VERSION ""

NS_ :

BS_:

BU_: XXX EPS

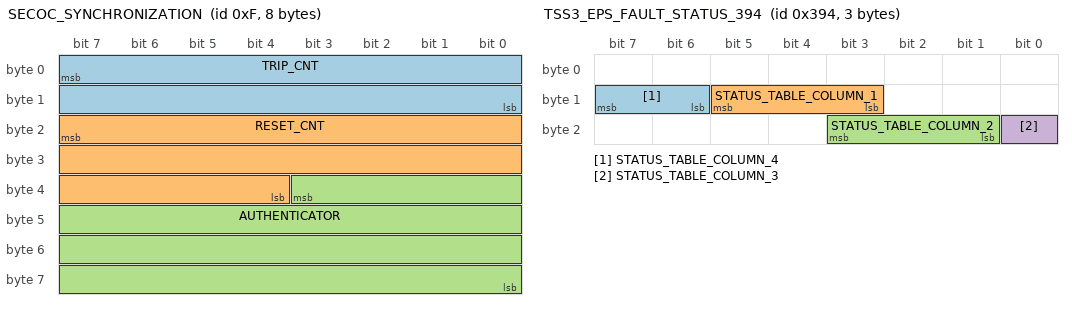
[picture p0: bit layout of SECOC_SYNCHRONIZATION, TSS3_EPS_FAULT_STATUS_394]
BO_ 15 SECOC_SYNCHRONIZATION: 8 XXX
 SG_ TRIP_CNT : 7|16@0+ (1,0) [0|65535] "" XXX
 SG_ RESET_CNT : 23|20@0+ (1,0) [0|1048575] "" XXX
 SG_ AUTHENTICATOR : 35|28@0+ (1,0) [0|268435455] "" XXX

BO_ 37 STEER_ANGLE_SENSOR: 32 XXX
 SG_ STEER_ANGLE : 3|12@0- (1.5,0) [-500|500] "deg" XXX
 SG_ STEER_FRACTION : 39|4@0- (0.1,0) [-0.7|0.7] "deg" XXX
 SG_ STEER_RATE : 35|12@0- (1,0) [-2000|2000] "deg/s" XXX

BO_ 48 TSS3_EPS_TELEMETRY: 32 EPS
 SG_ STEERING_WHEEL_TORQUE_TRUNC : 7|8@0- (0.1,0) [-12.8|12.7] "Nm" XXX
 SG_ EPS_STATUS_B6_BIT3 : 51|1@0+ (1,0) [0|1] "" XXX
 SG_ STEERING_FAULT_INHIBIT_STATUS : 50|1@0+ (1,0) [0|1] "" XXX
 SG_ EPS_STATUS_B6_BIT1 : 49|1@0+ (1,0) [0|1] "" XXX
 SG_ DRIVER_TORQUE_INVALID : 48|1@0+ (1,0) [0|1] "" XXX
 SG_ ADDITIVE_BYTE_7 : 63|8@0+ (1,0) [0|255] "" XXX
 SG_ STEERING_WHEEL_TORQUE_COARSE : 71|8@0- (0.1,0) [-12.8|12.7] "Nm" XXX
 SG_ STEERING_WHEEL_TORQUE_FINE : 139|4@0- (0.01,0) [-0.08|0.07] "Nm" XXX

BO_ 254 TSS3_CRUISE_SWITCH: 32 XXX
 SG_ MAIN_BUTTON : 58|1@0+ (1,0) [0|1] "" XXX
 SG_ RES_BUTTON : 31|1@0+ (1,0) [0|1] "" XXX
 SG_ RES_BUTTON_MIRROR_N : 55|1@0+ (1,0) [0|1] "" XXX
 SG_ SET_BUTTON : 39|1@0+ (1,0) [0|1] "" XXX
 SG_ SET_BUTTON_MIRROR_N : 62|1@0+ (1,0) [0|1] "" XXX
 SG_ CANCEL_BUTTON : 38|1@0+ (1,0) [0|1] "" XXX
 SG_ CANCEL_BUTTON_MIRROR_N : 61|1@0+ (1,0) [0|1] "" XXX

BO_ 138 TSS3_LATERAL_REQUEST: 32 XXX
 SG_ CRUISE_OPERATING_LATCH : 27|1@0+ (1,0) [0|1] "" XXX
 SG_ LATERAL_REQUEST_ACTIVE_FLAG : 39|1@0+ (1,0) [0|1] "" XXX
 SG_ CRUISE_SUBSTATE_1 : 55|8@0+ (1,0) [0|255] "" XXX
 SG_ CRUISE_SUBSTATE_2 : 63|8@0+ (1,0) [0|255] "" XXX
 SG_ REQUEST_WORD_B8 : 71|16@0- (1,0) [-32768|32767] "" XXX
 SG_ SET_SPEED : 87|8@0+ (1,0) [0|255] "km/h" XXX
 SG_ REQUEST_WORD_B8_MIRROR : 95|16@0- (1,0) [-32768|32767] "" XXX
 SG_ RESERVED_16BIT_B13 : 111|16@0- (1,0) [-32768|32767] "" XXX
 SG_ RESERVED_16BIT_B16 : 135|16@0- (1,0) [-32768|32767] "" XXX
 SG_ LATERAL_REQUEST_ANGLE : 151|16@0- (0.057302742,0) [-1877.696|1877.639] "deg" XXX
 SG_ CRUISE_STATE_B20 : 167|2@0+ (1,0) [0|3] "" XXX
 SG_ TARGET_LATERAL_ID : 173|6@0+ (1,0) [0|63] "" XXX
 SG_ CRUISE_STATE_B22 : 180|1@0+ (1,0) [0|1] "" XXX
 SG_ COOPERATIVE_SUBSTATE_FLAG : 189|1@0+ (1,0) [0|1] "" XXX
 SG_ LATERAL_REQUEST_LEVEL : 199|8@0+ (1,0) [0|255] "%" XXX
 SG_ SEQUENCE : 213|6@0+ (1,0) [0|63] "" XXX
 SG_ FRESHNESS_MESSAGE_LSB2 : 231|2@0+ (1,0) [0|3] "" XXX
 SG_ FRESHNESS_RESET_LSB2 : 229|2@0+ (1,0) [0|3] "" XXX
 SG_ CMAC_MSB28 : 227|28@0+ (1,0) [0|268435455] "" XXX

BO_ 849 TSS3_EPS_STATUS_351: 4 XXX
 SG_ STATUS_CODE : 23|3@0+ (1,0) [0|7] "" XXX
 SG_ STATUS_FLAG : 20|1@0+ (1,0) [0|1] "" XXX

BO_ 916 TSS3_EPS_FAULT_STATUS_394: 3 XXX
 SG_ STATUS_TABLE_COLUMN_4 : 15|2@0+ (1,0) [0|3] "" XXX
 SG_ STATUS_TABLE_COLUMN_1 : 13|3@0+ (1,0) [0|7] "" XXX
 SG_ STATUS_TABLE_COLUMN_2 : 19|3@0+ (1,0) [0|7] "" XXX
 SG_ STATUS_TABLE_COLUMN_3 : 16|1@0+ (1,0) [0|1] "" XXX

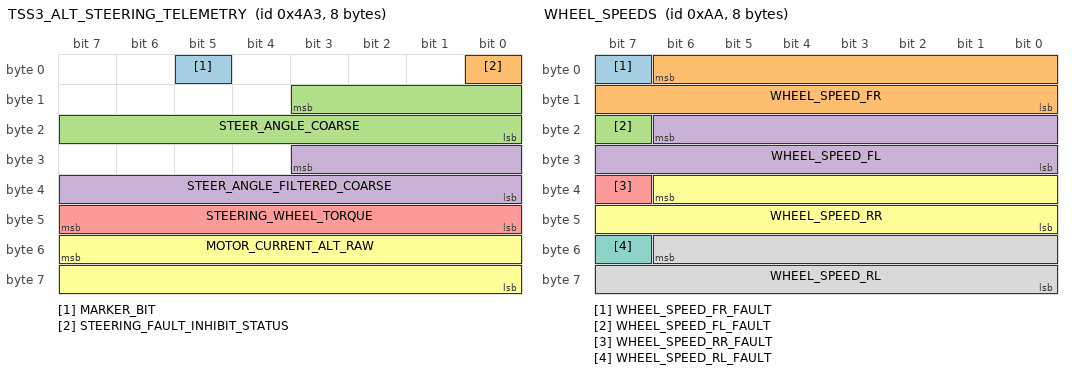
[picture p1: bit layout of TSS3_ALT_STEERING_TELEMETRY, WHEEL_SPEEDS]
BO_ 1187 TSS3_ALT_STEERING_TELEMETRY: 8 XXX
 SG_ MARKER_BIT : 5|1@0+ (1,0) [0|1] "" XXX
 SG_ STEERING_FAULT_INHIBIT_STATUS : 0|1@0+ (1,0) [0|1] "" XXX
 SG_ STEER_ANGLE_COARSE : 11|12@0- (1.5,0) [-3072|3070.5] "deg" XXX
 SG_ STEER_ANGLE_FILTERED_COARSE : 27|12@0- (1.5,0) [-3072|3070.5] "deg" XXX
 SG_ STEERING_WHEEL_TORQUE : 47|8@0- (0.1,0) [-12.8|12.7] "Nm" XXX
 SG_ MOTOR_CURRENT_ALT_RAW : 55|16@0- (1,0) [-32768|32767] "" XXX

BO_ 170 WHEEL_SPEEDS: 8 XXX
 SG_ WHEEL_SPEED_FR_FAULT : 7|1@0+ (1,0) [0|1] "" XXX
 SG_ WHEEL_SPEED_FR : 6|15@0+ (0.01,-67.67) [-67.67|260] "km/h" XXX
 SG_ WHEEL_SPEED_FL_FAULT : 23|1@0+ (1,0) [0|1] "" XXX
 SG_ WHEEL_SPEED_FL : 22|15@0+ (0.01,-67.67) [-67.67|260] "km/h" XXX
 SG_ WHEEL_SPEED_RR_FAULT : 39|1@0+ (1,0) [0|1] "" XXX
 SG_ WHEEL_SPEED_RR : 38|15@0+ (0.01,-67.67) [-67.67|260] "km/h" XXX
 SG_ WHEEL_SPEED_RL_FAULT : 55|1@0+ (1,0) [0|1] "" XXX
 SG_ WHEEL_SPEED_RL : 54|15@0+ (0.01,-67.67) [-67.67|260] "km/h" XXX

BO_ 182 TSS3_LATERAL_CONTROL: 32 XXX
 SG_ TARGET_LATERAL_ID : 29|6@0+ (1,0) [0|63] "" XXX
 SG_ TARGET_STEERING_ANGLE : 39|16@0- (0.057302742,0) [-99.9933|99.9933] "deg" XXX
 SG_ SIGNAL263_B6_BIT7 : 55|1@0+ (1,0) [0|1] "" XXX
 SG_ SIGNAL264_B6_BITS6_4 : 54|3@0+ (1,0) [0|7] "" XXX
 SG_ ADDITIVE_TERM_SUPPRESS : 50|1@0+ (1,0) [0|1] "" XXX
 SG_ SIGNAL266_B6_BITS1_0 : 49|2@0+ (1,0) [0|3] "" XXX
 SG_ SIGNAL267_B7_BITS7_6 : 63|2@0+ (1,0) [0|3] "" XXX
 SG_ SEQUENCE : 61|6@0+ (1,0) [0|63] "" XXX
 SG_ CONTRIBUTION_PCT_1 : 71|8@0+ (1,0) [0|255] "%" XXX
 SG_ CONTRIBUTION_PCT_2 : 79|8@0+ (1,0) [0|255] "%" XXX
 SG_ SIGNAL271_B10_BIT7 : 87|1@0+ (1,0) [0|1] "" XXX
 SG_ SIGNAL272_B10_BIT5 : 85|1@0+ (1,0) [0|1] "" XXX
 SG_ SIGNAL273_B10_BITS2_0 : 82|3@0+ (1,0) [0|7] "" XXX
 SG_ FRESHNESS_MESSAGE_LSB2 : 231|2@0+ (1,0) [0|3] "" XXX
 SG_ FRESHNESS_RESET_LSB2 : 229|2@0+ (1,0) [0|3] "" XXX
 SG_ CMAC_MSB28 : 227|28@0+ (1,0) [0|268435455] "" XXX

BO_ 593 TSS3_CRUISE_DISPLAY: 8 XXX
 SG_ CRUISE_MAIN_STATE : 12|1@0+ (1,0) [0|1] "" XXX
 SG_ UI_SET_SPEED : 23|8@0+ (1,0) [0|255] "" XXX

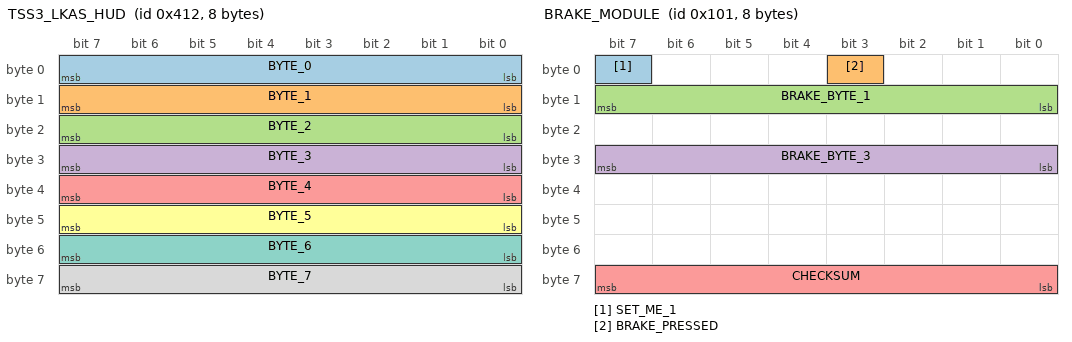
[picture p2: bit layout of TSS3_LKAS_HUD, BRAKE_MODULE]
BO_ 1042 TSS3_LKAS_HUD: 8 XXX
 SG_ BYTE_0 : 7|8@0+ (1,0) [0|255] "" XXX
 SG_ BYTE_1 : 15|8@0+ (1,0) [0|255] "" XXX
 SG_ BYTE_2 : 23|8@0+ (1,0) [0|255] "" XXX
 SG_ BYTE_3 : 31|8@0+ (1,0) [0|255] "" XXX
 SG_ BYTE_4 : 39|8@0+ (1,0) [0|255] "" XXX
 SG_ BYTE_5 : 47|8@0+ (1,0) [0|255] "" XXX
 SG_ BYTE_6 : 55|8@0+ (1,0) [0|255] "" XXX
 SG_ BYTE_7 : 63|8@0+ (1,0) [0|255] "" XXX

BO_ 257 BRAKE_MODULE: 8 XXX
 SG_ SET_ME_1 : 7|1@0+ (1,0) [0|1] "" XXX
 SG_ BRAKE_PRESSED : 3|1@0+ (1,0) [0|1] "" XXX
 SG_ BRAKE_BYTE_1 : 15|8@0+ (1,0) [0|255] "" XXX
 SG_ BRAKE_BYTE_3 : 31|8@0+ (1,0) [0|255] "" XXX
 SG_ CHECKSUM : 63|8@0+ (1,0) [0|255] "" XXX

BO_ 278 GAS_PEDAL: 8 XXX
 SG_ GAS_PEDAL_USER : 15|8@0+ (0.005,0) [0|1.275] "" XXX

BO_ 295 GEAR_PACKET_HYBRID: 8 XXX
 SG_ GEAR : 47|4@0+ (1,0) [0|15] "" XXX
 SG_ CHECKSUM : 63|8@0+ (1,0) [0|255] "" XXX

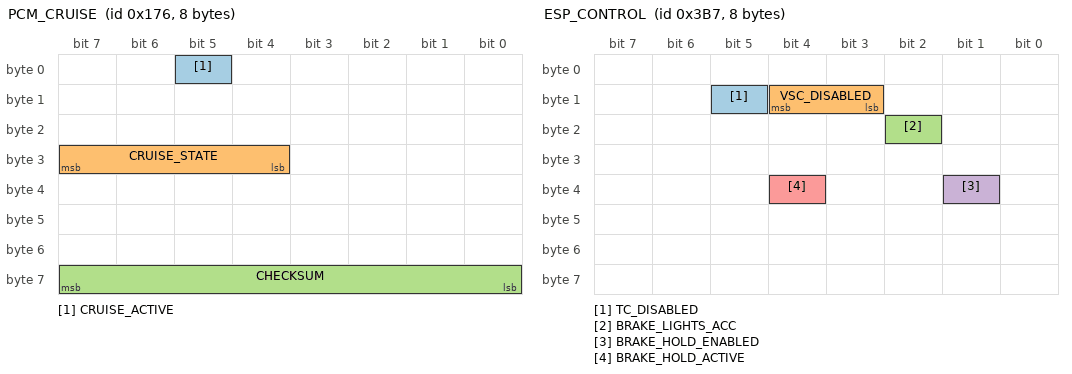
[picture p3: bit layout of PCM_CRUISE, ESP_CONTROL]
BO_ 374 PCM_CRUISE: 8 XXX
 SG_ CRUISE_ACTIVE : 5|1@0+ (1,0) [0|1] "" XXX
 SG_ CRUISE_STATE : 31|4@0+ (1,0) [0|15] "" XXX
 SG_ CHECKSUM : 63|8@0+ (1,0) [0|255] "" XXX

BO_ 1310 TSS3_READY_STATUS: 8 XXX
 SG_ READY_STATUS : 7|1@0+ (1,0) [0|1] "" XXX

BO_ 1556 BLINKERS_STATE: 8 XXX
 SG_ TURN_SIGNALS : 29|2@0+ (1,0) [0|3] "" XXX

BO_ 951 ESP_CONTROL: 8 ESP
 SG_ TC_DISABLED : 13|1@0+ (1,0) [0|1] "" XXX
 SG_ VSC_DISABLED : 12|2@0+ (1,0) [0|1] "" XXX
 SG_ BRAKE_LIGHTS_ACC : 18|1@0+ (1,0) [0|1] "" XXX
 SG_ BRAKE_HOLD_ENABLED : 33|1@1+ (1,0) [0|1] "" XXX
 SG_ BRAKE_HOLD_ACTIVE : 36|1@0+ (1,0) [0|1] "" XXX

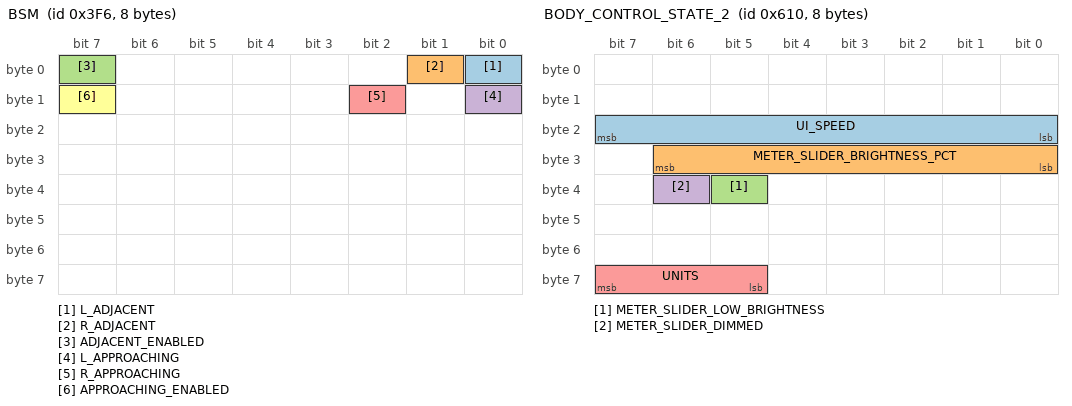
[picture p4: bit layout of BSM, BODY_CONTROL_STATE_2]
BO_ 1014 BSM: 8 XXX
 SG_ L_ADJACENT : 0|1@0+ (1,0) [0|1] "" XXX
 SG_ R_ADJACENT : 1|1@0+ (1,0) [0|1] "" XXX
 SG_ ADJACENT_ENABLED : 7|1@0+ (1,0) [0|1] "" XXX
 SG_ L_APPROACHING : 8|1@0+ (1,0) [0|1] "" XXX
 SG_ R_APPROACHING : 10|1@0+ (1,0) [0|1] "" XXX
 SG_ APPROACHING_ENABLED : 15|1@0+ (1,0) [0|1] "" XXX

BO_ 1552 BODY_CONTROL_STATE_2: 8 XXX
 SG_ UI_SPEED : 23|8@0+ (1,0) [0|255] "km/h" XXX
 SG_ METER_SLIDER_BRIGHTNESS_PCT : 30|7@0+ (1,0) [12|100] "%" XXX
 SG_ METER_SLIDER_LOW_BRIGHTNESS : 37|1@0+ (1,0) [0|1] "" XXX
 SG_ METER_SLIDER_DIMMED : 38|1@0+ (1,0) [0|1] "" XXX
 SG_ UNITS : 63|3@0+ (1,0) [0|4] "" XXX

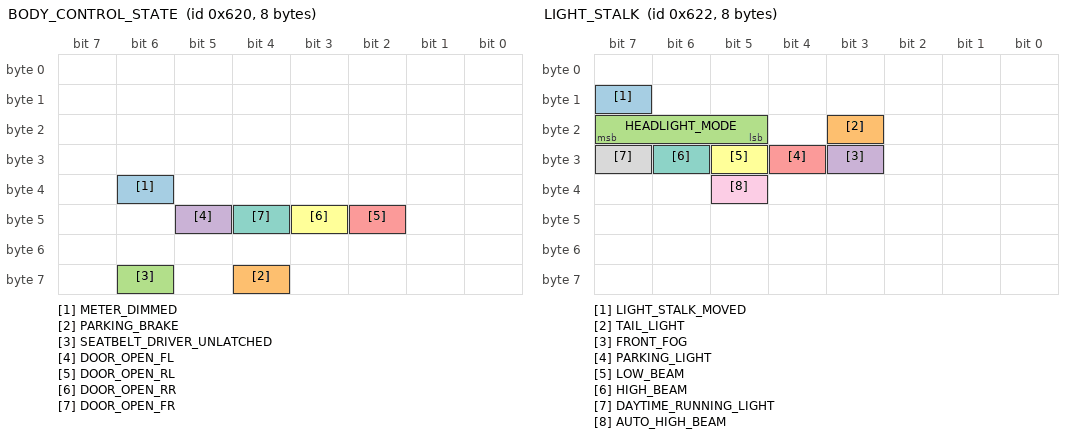
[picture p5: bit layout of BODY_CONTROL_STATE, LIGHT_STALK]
BO_ 1568 BODY_CONTROL_STATE: 8 XXX
 SG_ METER_DIMMED : 38|1@0+ (1,0) [0|1] "" XXX
 SG_ PARKING_BRAKE : 60|1@0+ (1,0) [0|1] "" XXX
 SG_ SEATBELT_DRIVER_UNLATCHED : 62|1@0+ (1,0) [0|1] "" XXX
 SG_ DOOR_OPEN_FL : 45|1@0+ (1,0) [0|1] "" XXX
 SG_ DOOR_OPEN_RL : 42|1@0+ (1,0) [0|1] "" XXX
 SG_ DOOR_OPEN_RR : 43|1@0+ (1,0) [0|1] "" XXX
 SG_ DOOR_OPEN_FR : 44|1@0+ (1,0) [0|1] "" XXX

BO_ 1570 LIGHT_STALK: 8 SCM
 SG_ LIGHT_STALK_MOVED : 15|1@0+ (1,0) [0|1] "" XXX
 SG_ TAIL_LIGHT : 19|1@0+ (1,0) [0|1] "" XXX
 SG_ HEADLIGHT_MODE : 21|3@1+ (1,0) [0|7] "" XXX
 SG_ FRONT_FOG : 27|1@0+ (1,0) [0|1] "" XXX
 SG_ PARKING_LIGHT : 28|1@0+ (1,0) [0|1] "" XXX
 SG_ LOW_BEAM : 29|1@0+ (1,0) [0|1] "" XXX
 SG_ HIGH_BEAM : 30|1@0+ (1,0) [0|1] "" XXX
 SG_ DAYTIME_RUNNING_LIGHT : 31|1@0+ (1,0) [0|1] "" XXX
 SG_ AUTO_HIGH_BEAM : 37|1@0+ (1,0) [0|1] "" XXX

CM_ BO_ 138 "Exact 2026 Camry lateral-request carrier recovered from two relay-correct drives (44,613 deduped bus-0 frames; every field boundary in this message is backed by a full both-drive byte census partitioned by B21 state). This is not exact-F33 normal ingress or generated-COM transmit and is defined for passive analysis only. B28:B31 strongly match Toyota ordinary-P5 FV4+MAC28 structure; exact producer/profile/key/CMAC remain unresolved. Stock LTA does not establish or require an 0x08A-to-B6 transform.";
CM_ SG_ 138 LATERAL_REQUEST_ANGLE "Signed B18:B19 structural request-angle quantity. Under ID0 it tracks measured 0x025 angle at 1024/17870 deg/count; under ID11 its correlation shifts toward future measured angle. Current EMPS_P5 DID 0x1CEE monitor 2071 has a different 1.5 deg/count diagnostic representation, and exact 8965F3307000 does not implement DID 0x1CEE, so that OEM name is not transferred to this wire field. The matching scale does not establish an 0x08A-to-B6 path.";
CM_ SG_ 138 TARGET_LATERAL_ID "Retained Camry states are exactly 0, 11, and 18. Current EMPS_P5 DID 0x1CEE monitor 2069 provides the generic generation-20 Target Lateral ID dictionary, while exact 8965F3307000 does not implement that DID; the matching values therefore corroborate interpretation but do not form an exact-target diagnostic join. Upper two bits are zero in all retained frames, so the 6-bit boundary remains an encoding assumption.";
CM_ SG_ 138 SEQUENCE "Modulo-64 application sequence counter; upper two bits never observed nonzero, so the 6-bit boundary is an encoding assumption. On every same-reset B26+1 pair in both retained drives the B28 FV4 message-low2 also advances +1 (18,727 / 21,989 pairs), consistent with the freshness counter tracking this sequence.";
CM_ SG_ 138 CRUISE_OPERATING_LATCH "B3[3]; value 8 is a reproducible cruise operating-state latch: six rising edges follow six effective MAIN presses by 0.17..0.29 s and CANCEL clears it within 0.03..0.07 s. B21=11 occurs only with this latch set and B21=18 only with it clear.";
CM_ SG_ 138 CRUISE_SUBSTATE_1 "B6 cruise substate. In the retained road corpus 45 is the ordinary active value and 44 is the accelerator-override companion; both are retained at zero-speed ACC hold. Other rare transition values exist. Structural name; not OEM-joined.";
CM_ SG_ 138 CRUISE_SUBSTATE_2 "B7 cruise substate. Ordinary active cruise is 71, accelerator override is 70, while 103/102 form the delayed zero-speed ACC standstill/resume-required state (normal/accelerator override). Across three retained episodes those 198 frames are all at exact zero speed and all episodes clear with accelerator input before motion; no RES-button clear join is established. B7 bit5 alone is not sufficient: rare moving transition value 101 is observed. Structural state mapping; not an OEM field-name join.";
CM_ SG_ 138 REQUEST_WORD_B8 "Signed16 B8:B9, byte-identical to B11:B12. When cruise is latched (B3[3] and B10=set speed) this tracks (set speed − 0x0AA km/h) at r≈0.99, slope ~120–131 counts/km/h (near Q7). Longitudinal sidecar on the TSS request PDU, not a pinion. Not a GTS+ DID join; do not send as a command.";
CM_ SG_ 138 REQUEST_WORD_B8_MIRROR "Byte-identical redundant copy of REQUEST_WORD_B8 at B11:B12; equality holds in 44,613/44,613 deduped retained bus-0 frames across both drives.";
CM_ SG_ 138 SET_SPEED "B10 latched cruise set speed, 1 km/h/count: three RES+ presses change 66->67->68->70 and SET-/CANCEL transitions close through independent 0x0AA vehicle speed. Zero when cruise is off. FRC_P5 DID 0x1901 Memory Vehicle Speed corroborates the set-speed concept in km/h without proving the wire mapping.";
CM_ SG_ 593 CRUISE_MAIN_STATE "B1[4] persistent cruise-availability/latch state. On routes 0000002c--c784367b7e and 0000003d--0e812cecba it starts 0, rises 129.9/160.4 ms after the first effective MAIN activation, and remains 1 through five observed CANCEL events while 0x08A CRUISE_OPERATING_LATCH clears. Independent relay-correct 2026-08-27 evidence additionally shows one B1[4] rise after the first MAIN activation and zero falls while later validated MAIN presses drive the 0x08A operation latch 1->0 twice, proving B1[4] is not the physical MAIN switch. Ignition-off/reset fall semantics and the OEM field name remain unjoined; this is the observed state used for openpilot cruiseState.available.";
CM_ SG_ 593 UI_SET_SPEED "Exact maintainer Camry imperial-cluster set speed. Route 0000002c--c784367b7e B2 transitions 0->21->22->23->24->25->19->21->19 across stock cruise activation/re-engagement and four RES+ presses; the RES+ UI transitions precede the corresponding 0x08A internal-km/h SET_SPEED updates by about 11 ms. This is the TSS3 analog of Toyota's separate UI_SET_SPEED semantic; unit transfer is exact only for the observed imperial cluster.";
CM_ SG_ 138 RESERVED_16BIT_B13 "B13:B14 constant 0x7FFF in all retained frames: Toyota unpublished signed16 pinion sentinel (ADU 2A04/1B40 invalid). EPS-facing 1B40_3 copy is not published on this PDU.";
CM_ SG_ 138 RESERVED_16BIT_B16 "B16:B17 constant 0x7FFF in all retained frames: same unpublished signed16 pinion sentinel as B13:B14.";
CM_ SG_ 138 CRUISE_STATE_B20 "B20[7:6]: 0b11 exactly when the cruise operating latch is set (0b10 in 26 transitional frames); zero with cruise off. Structural name; not OEM-joined.";
CM_ SG_ 138 CRUISE_STATE_B22 "B22[4] set exactly when the cruise operating latch is set. Structural name; not OEM-joined.";
CM_ SG_ 138 COOPERATIVE_SUBSTATE_FLAG "B23[5] is set in every retained SDG (B21=18) row and toggles 0/1 within LTA/LCA intervals (drive A 376/646 frames set; drive B 229/2288). EMPS_P5 DID 0x1CEE monitor 2070 carries a 0/1 Cooperative Control in Progress Flag; identity with this bit is unjoined.";
CM_ SG_ 138 LATERAL_REQUEST_LEVEL "B24 steering assist gain, TSS3 recorder 5282 / LTA 5631 LSB 0.01 (DBC stores the raw 0–100 counts: 100=1.00, 50=0.50). 100 in every retained LTA/LCA (B21=11) frame, 50 in every SDG (B21=18) frame. Damping (5282_4) is not on this PDU (B25=0).";
CM_ SG_ 138 FRESHNESS_MESSAGE_LSB2 "SecOC FV4 B28[7:6] message-counter low2; advances +1 on every same-reset B26+1 pair (CORR-135 structural match against preceding authenticated 0x00F).";
CM_ SG_ 138 FRESHNESS_RESET_LSB2 "SecOC FV4 B28[5:4] reset-counter low2; agrees with the preceding authenticated 0x00F on 19,868/20,615 drive-A and 23,093/23,996 drive-B eligible frames.";
CM_ SG_ 138 CMAC_MSB28 "B28[3:0]..B31[7:4]: effectively frame-unique in both retained drives, matching the Toyota ordinary-P5 transmitted MAC28. Exact sender key/profile remains unrecovered.";
CM_ BO_ 593 "TSS3 Camry cluster cruise state/display carrier. B1[4] separates persistent cruise main/availability from the 0x08A operating latch, while B2 follows the vehicle UI set speed in the currently selected display units. Interpret units through legacy BODY_CONTROL_STATE_2.UNITS, matching upstream Toyota CarState.";
CM_ BO_ 1042 "Raw-byte TSS3 Camry FRC-side HUD carrier retained for stock-clone replacement. 2026-09-06 highway captures join B1[3:2]=3 to the native hands-off warning cycle and observe B2[6] only as a rare escalation inside that cycle. Other byte semantics remain intentionally unmapped.";
CM_ SG_ 593 UI_SET_SPEED "Set speed shown in the vehicle UI, in the vehicle-selected unit. Retained maintainer Camry: 21->22->23->24->25 across four RES+ presses while internal 0x08A B10 follows 32->34->35->37->39 km/h.";
CM_ SG_ 1552 UNITS "Legacy Toyota vehicle-unit selector retained on TSS3. Upstream Toyota treats values 1/2 as metric and other values as imperial; maintainer Camry is observed at 0 in imperial configuration.";
CM_ BO_ 849 "F33/H/F retained EPS status PDU. Only B2[7:5] status code and B2[4] companion flag are statically closed; do not map to temporary/permanent fault without live transitions.";
CM_ BO_ 916 "F33/H/F retained EPS 17-state fault/status projection. The four transmitted table columns are lossy; state 0 is clear/normal candidate only, not a Ready or openpilot fault policy.";
CM_ BO_ 1187 "Exact F33 packers 0x4C000/0x4C14E/0x4C7AA close this retained alternate steering telemetry PDU. Current Camry normal-harness captures do not observe its route, so availability/policy stays live-bound.";
CM_ SG_ 1187 STEER_ANGLE_COARSE "Exact F33: signed12 0x025 coarse steering-angle source, 1.5 deg/count, packed in B1[3:0]:B2.";
CM_ SG_ 1187 STEER_ANGLE_FILTERED_COARSE "Exact F33: filtered/voted signed12 steering-angle quantity derived from the same 0x025 coarse source, packed in B3[3:0]:B4.";
CM_ SG_ 1187 MOTOR_CURRENT_ALT_RAW "Exact F33 0x4C000 producer computes this signed16 packed integer as source GP-0x50E8 * -100 / 0x80 before B6:B7. H/F joins the homologous source to Motor Actual Current (Q Axis), but F33 DID 0x1151 reads GP-0x50F2 instead; no physical unit is assigned until a target-native source join or live correlation closes it.";
CM_ SG_ 1187 STEERING_WHEEL_TORQUE "Techstream DID 0x1035 Steering Wheel Torque, 0.1 Nm/count.";
CM_ SG_ 182 ADDITIVE_TERM_SUPPRESS "Exact F33 receiver: value 1 suppresses one recovered additive steering term. This is not an OEM field-name claim.";
CM_ SG_ 182 CONTRIBUTION_PCT_1 "Exact F33 receiver consumes this byte as a /100 contribution; zero removes the contribution. OEM field name remains unknown.";
CM_ SG_ 182 CONTRIBUTION_PCT_2 "Exact F33 receiver consumes this byte as a /100 contribution; zero removes the contribution. OEM field name remains unknown.";
CM_ SG_ 182 FRESHNESS_MESSAGE_LSB2 "SecOC FV4 high two bits: message-counter low2.";
CM_ SG_ 182 FRESHNESS_RESET_LSB2 "SecOC FV4 low two bits: reset-counter low2.";
CM_ SG_ 182 CMAC_MSB28 "SecOC transmitted authenticator: AES-CMAC MSB28 over DataID 0x00B6, B0..B27, and full freshness.";
CM_ BO_ 37 "TSS3 Corolla uses the legacy steering angle/fraction/rate bit positions inside a 32-byte CAN-FD PDU; exact H firmware and two driving captures support these fields.";
CM_ BO_ 48 "Exact H/F EPS transmits this 32-byte PDU. Driver torque and B6 safety/status gates are target-native recovered fields; byte 7 equals sum(bytes 0..6)+0x38 modulo 256.";
CM_ SG_ 48 STEERING_WHEEL_TORQUE_TRUNC "DID 0x1035 Steering Wheel Torque source, saturating truncation-toward-zero 0.1 Nm view. It can differ from COARSE by one count due to firmware rounding.";
CM_ SG_ 48 STEERING_WHEEL_TORQUE_COARSE "Coarse component of exact physical Steering Wheel Torque reconstruction.";
CM_ SG_ 48 STEERING_WHEEL_TORQUE_FINE "Signed hundredths remainder. Exact torque = COARSE + FINE; Span exercises -0.05..+0.05 Nm remainder.";
CM_ SG_ 254 RES_BUTTON_MIRROR_N "Redundant active-low complement of RES_BUTTON; both are observed on the physical switch carrier.";
CM_ SG_ 254 SET_BUTTON_MIRROR_N "Redundant active-low complement of SET_BUTTON; both are observed on the physical switch carrier.";
CM_ SG_ 254 CANCEL_BUTTON_MIRROR_N "Redundant active-low complement of CANCEL_BUTTON; both are observed on the physical switch carrier.";
CM_ SG_ 48 STEERING_FAULT_INHIBIT_STATUS "Target-native selected steering fault/inhibit status aggregate from FEBE7DAE; nominal-clear in retained driving captures. This is not an exhaustive EPS-fault bitmap, and no retained asserted/recovery episode classifies it as temporary or permanent for openpilot policy.";
CM_ SG_ 48 DRIVER_TORQUE_INVALID "Target-native driver-torque invalid/inhibit gate from FEBE7DB2; nominal-clear in all 6000 tracked Span frames.";
CM_ SG_ 48 EPS_STATUS_B6_BIT1 "Runtime status bit from FEBE7DB3; exact OEM meaning unresolved.";
CM_ SG_ 48 EPS_STATUS_B6_BIT3 "Runtime status bit from FEBE7E09; exact OEM meaning unresolved.";
CM_ BO_ 182 "Exact H/F protected lateral receiver PDU. Receiver-side fields are defined for analysis only; transmission remains disabled.";
CM_ SG_ 182 TARGET_LATERAL_ID "Techstream Target Lateral ID; exact H accepts 1=PCS, 4=LDA, 10=Hands Off LTA, 11=LTA/LCA, 19=PDA. 0 means no request.";
CM_ SG_ 182 TARGET_STEERING_ANGLE "Controller-equivalent scale is exactly 1024/17870 deg/count (~0.057302742 deg/count). OEM wire-unit label remains unjoined.";
CM_ SG_ 182 SEQUENCE "Exact H receiver treats this as a modulo-64 sequence counter with effective gap cap 8.";
CM_ SG_ 295 GEAR "Only raw 3=D has been dynamically validated on the tracked TSS3 Corolla capture; remaining enum values are retained from Toyota prior art pending target transitions.";
CM_ SG_ 374 CRUISE_ACTIVE "Wire location/checksum are retained Toyota prior art and observed on moving TSS3 Corolla captures; an active cruise transition has not yet been captured.";
CM_ SG_ 1310 READY_STATUS "Exact H PDU29 signal154: incoming 0x51E B0[7] feeds DID 0x1033 Ready Status. Both retained operational captures show value 1 only; do not infer Ready=0 fault policy without a transition.";

VAL_ 138 TARGET_LATERAL_ID 63 "Driver Operation" 49 "Self-Propelled Transport" 45 "DES (Lv.4)" 43 "EM (Lv.4)" 41 "AD (Lv.4)" 39 "DES (Lv.3)" 37 "EM (Lv.3)" 35 "AD (Lv.3)" 27 "Remote Parking" 25 "AP" 19 "PDA" 18 "SDG" 15 "DESA (Deceleration Stop Control)" 13 "DESA (Slow Deceleration Control)" 11 "LTA/LCA" 10 "Hands Off LTA" 4 "LDA" 1 "PCS" 0 "No Request (Manual Operation)";
VAL_ 182 TARGET_LATERAL_ID 63 "Driver Operation" 49 "Self-Propelled Transport" 45 "DES (Lv.4)" 43 "EM (Lv.4)" 41 "AD (Lv.4)" 39 "DES (Lv.3)" 37 "EM (Lv.3)" 35 "AD (Lv.3)" 27 "Remote Parking" 25 "AP" 19 "PDA" 18 "SDG" 15 "DESA (Deceleration Stop Control)" 13 "DESA (Slow Deceleration Control)" 11 "LTA/LCA" 10 "Hands Off LTA" 4 "LDA" 1 "PCS" 0 "No Request (Manual Operation)";
VAL_ 295 GEAR 0 "P" 1 "R" 2 "N" 3 "D" 4 "B" ;
VAL_ 1556 TURN_SIGNALS 3 "hazard" 2 "right" 1 "left" 0 "none";
